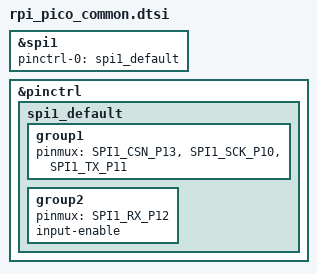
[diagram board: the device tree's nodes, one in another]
&spi1 {
	status = "okay";
	pinctrl-0 = <&spi1_default>;
	pinctrl-names = "default";
};

&pinctrl {
	spi1_default: spi1_default {
		group1 {
			pinmux = <SPI1_CSN_P13>, <SPI1_SCK_P10>, <SPI1_TX_P11>;
		};
		group2 {
			pinmux = <SPI1_RX_P12>;
			input-enable;
		};
	};
};
